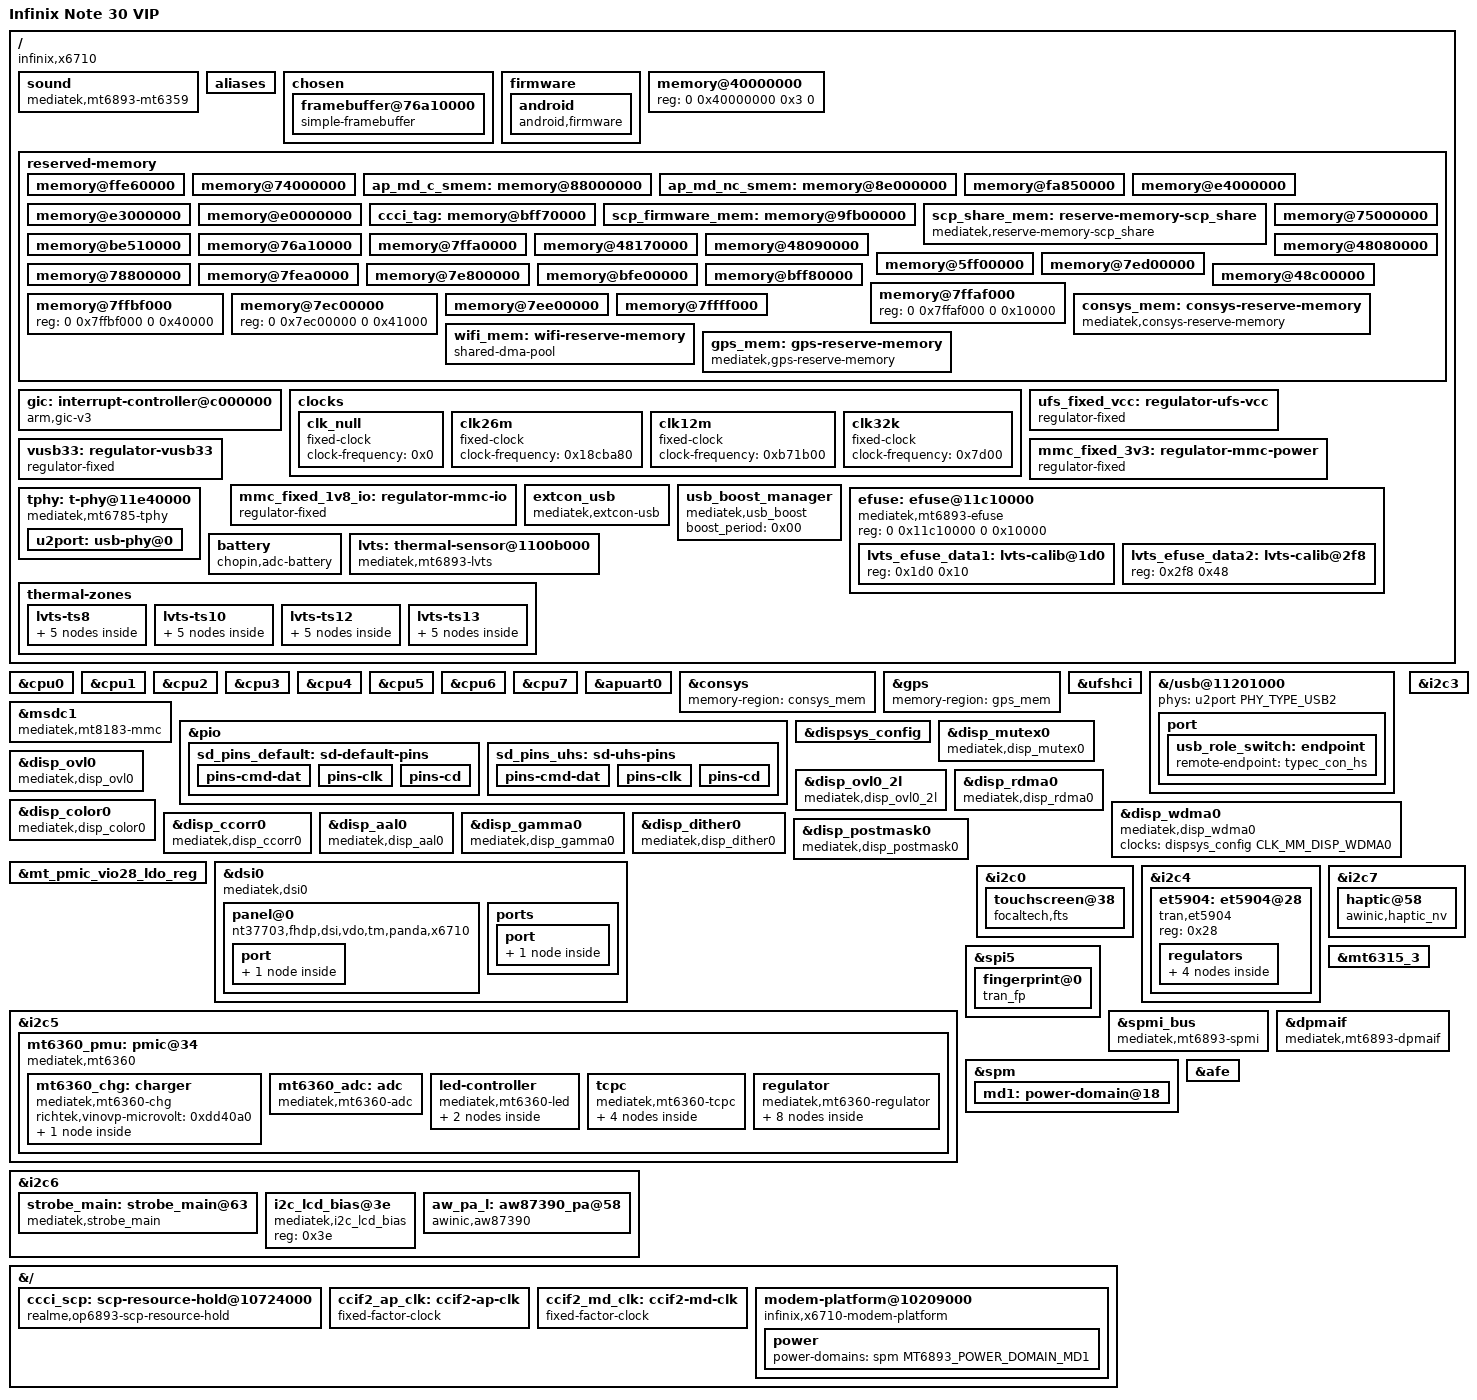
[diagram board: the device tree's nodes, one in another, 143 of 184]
// SPDX-License-Identifier: GPL-2.0-only
/*
 * Infinix Note 30 VIP (X6710)
 *
 * MediaTek MT6893Z/CZA handset.  The SoC side lives in mt6893.dtsi; this
 * file carries the board wiring: memory map, simplefb hand-off, PMIC,
 * UFS, USB, display, touch and the handful of I2C/SPI peripherals that
 * are populated on this board.
 */

/dts-v1/;

#include <dt-bindings/clock/mediatek,mt6893-clk.h>
#include <dt-bindings/power/mediatek,mt6893-power.h>
#include <dt-bindings/gpio/gpio.h>
#include <dt-bindings/interrupt-controller/arm-gic.h>
#include <dt-bindings/leds/common.h>
#include <dt-bindings/phy/phy.h>
#include <dt-bindings/thermal/mediatek,lvts-thermal.h>
#include <dt-bindings/thermal/thermal.h>
#include <dt-bindings/pinctrl/mt65xx.h>
#include <dt-bindings/reset/mediatek,mt6893-resets.h>
#include "mt6893.dtsi"

/ {
	model = "Infinix Note 30 VIP";
	chassis-type = "handset";
	compatible = "infinix,x6710", "mediatek,mt6893";

	interrupt-parent = <&gic>;
	#address-cells = <0x02>;
	#size-cells = <0x02>;

	/* Speaker card: AFE DL1 -> I2S3 -> stereo Awinic AW87390 smart PAs.
	 * The two AW87390 components (no DAI) attach as aux-devs.  The MTK AFE
	 * GPIO driver tolerates missing audio pinctrl states; I2S3 pins are
	 * muxed by the bootloader handoff, as with the display. */
	sound: sound {
		compatible = "mediatek,mt6893-mt6359";
		model = "mt6893_mt6359";
		mediatek,platform = <&afe>;
		status = "okay";

		/* Only one AW87390 is populated (i2c6 @0x58); the old second
		 * entry at 0x59 does not respond and blocked card binding.
		 */
		aux-devs = <&aw_pa_l>;
	};

	aliases {
		serial0 = &apuart0;

		/* The downstream DRM stack uses these IDs to identify blocks. */
		ovl0 = &disp_ovl0;
		ovl3 = &disp_ovl0_2l;
		rdma0 = &disp_rdma0;
		wdma0 = &disp_wdma0;
		color0 = &disp_color0;
		ccorr0 = &disp_ccorr0;
		aal0 = &disp_aal0;
		gamma0 = &disp_gamma0;
		dither0 = &disp_dither0;
		rsz0 = &disp_rsz0;
		postmask0 = &disp_postmask0;
		dsi0 = &dsi0;
	};

	chosen {
		#address-cells = <0x02>;
		#size-cells = <0x02>;
		ranges;

		stdout-path = "serial0:921600n8";

		/* 48-byte LK handoff header from the stock X6710 FDT:
		 * base=0xbff70000 size=0xa68 error=0 version=3 count=20
		 * load_flag=1, md_errors=0, tail padding=0. */
		ccci,modem_info_v2 = <0xf7bf 0x00 0x680a0000 0x00
				      0x3000000 0x14000000 0x1000000 0x00
				      0x00 0x00 0x00 0x00>;

		bootargs = "console=tty0 console=ttyS0,921600n8 clk_ignore_unused regulator_ignore_unused pd_ignore_unused loglevel=7 debug";

		framebuffer@76a10000 {
			compatible = "simple-framebuffer";
			reg = <0 0x76a10000 0 0x1df0000>;
			width = <1080>;
			height = <2400>;
			stride = <((1080 + 8) * 4)>;
			format = "a8r8g8b8";
			status = "okay";
		};
	};

	firmware {
		android {
			compatible = "android,firmware";
			hardware = "mt6893";
			mode = "normal";
		};
	};

	memory@40000000 {
		device_type = "memory";
		reg = <0 0x40000000 0x3 0>;
	};

	reserved-memory {
		#address-cells = <0x02>;
		#size-cells = <0x02>;
		ranges;

		/* ATF / secure monitor log */
		memory@ffe60000 {
			reg = <0 0xffe60000 0 0x190000>;
			no-map;
		};

		memory@74000000 {
			reg = <0 0x74000000 0 0xe30000>;
			no-map;
		};

		ap_md_c_smem: memory@88000000 {
			reg = <0 0x88000000 0 0x5560000>;
			no-map;
		};

		ap_md_nc_smem: memory@8e000000 {
			reg = <0 0x8e000000 0 0x910000>;
			no-map;
		};

		memory@fa850000 {
			reg = <0 0xfa850000 0 0x37b0000>;
			no-map;
		};

		memory@e4000000 {
			reg = <0 0xe4000000 0 0x7eb0000>;
			no-map;
		};

		memory@e3000000 {
			reg = <0 0xe3000000 0 0xf0000>;
			no-map;
		};

		memory@e0000000 {
			reg = <0 0xe0000000 0 0x2080000>;
			no-map;
		};

		ccci_tag: memory@bff70000 {
			reg = <0 0xbff70000 0 0x10000>;
			no-map;
		};

		/* Stock X6710 mblock-23-SCP-reserved: SCP firmware/TCM handoff. */
		scp_firmware_mem: memory@9fb00000 {
			reg = <0 0x9fb00000 0 0x400000>;
			no-map;
		};

		/* Stock X6710 reserve-memory-scp_share geometry. */
		scp_share_mem: reserve-memory-scp_share {
			compatible = "mediatek,reserve-memory-scp_share";
			no-map;
			size = <0 0x320000>;
			alignment = <0 0x1000000>;
			alloc-ranges = <0 0x50000000 0 0x40000000>;
		};

		memory@75000000 {
			reg = <0 0x75000000 0 0x10000>;
			no-map;
		};

		memory@be510000 {
			reg = <0 0xbe510000 0 0x18f0000>;
			no-map;
		};

		/* framebuffer handed over by uniLoader */
		memory@76a10000 {
			reg = <0 0x76a10000 0 0x1df0000>;
			no-map;
		};

		memory@7ffa0000 {
			reg = <0 0x7ffa0000 0 0x8000>;
			no-map;
		};

		memory@48170000 {
			reg = <0 0x48170000 0 0x10000>;
			no-map;
		};

		/* ramoops (see ramoops.mem_address=0x48090000) */
		memory@48090000 {
			reg = <0 0x48090000 0 0xe0000>;
			no-map;
		};

		memory@48080000 {
			reg = <0 0x48080000 0 0x10000>;
			no-map;
		};

		memory@5ff00000 {
			reg = <0 0x5ff00000 0 0x80000>;
			no-map;
		};

		memory@7ed00000 {
			reg = <0 0x7ed00000 0 0x100000>;
			no-map;
		};

		memory@78800000 {
			reg = <0 0x78800000 0 0x6000000>;
			no-map;
		};

		memory@7fea0000 {
			reg = <0 0x7fea0000 0 0x100000>;
			no-map;
		};

		memory@7e800000 {
			reg = <0 0x7e800000 0 0x400000>;
			no-map;
		};

		memory@bfe00000 {
			reg = <0 0xbfe00000 0 0x40000>;
			no-map;
		};

		memory@bff80000 {
			reg = <0 0xbff80000 0 0x80000>;
			no-map;
		};

		memory@48c00000 {
			reg = <0 0x48c00000 0 0x200000>;
			no-map;
		};

		memory@7ffaf000 {
			reg = <0 0x7ffaf000 0 0x10000>;
		};

		memory@7ffbf000 {
			reg = <0 0x7ffbf000 0 0x40000>;
		};

		memory@7ec00000 {
			reg = <0 0x7ec00000 0 0x41000>;
		};

		memory@7ee00000 {
			reg = <0 0x7ee00000 0 0x1000000>;
			no-map;
		};

		memory@7ffff000 {
			reg = <0 0x7ffff000 0 0x1000>;
			no-map;
		};

		/* Connectivity firmware/coredump EMI, allocated below 0x90000000. */
		consys_mem: consys-reserve-memory {
			compatible = "mediatek,consys-reserve-memory";
			no-map;
			size = <0x0 0x450000>;
			alignment = <0x0 0x1000000>;
			alloc-ranges = <0x0 0x50000000 0x0 0x40000000>;
		};

		wifi_mem: wifi-reserve-memory {
			compatible = "shared-dma-pool";
			no-map;
			size = <0x0 0xf20000>;
			alignment = <0x0 0x1000000>;
			alloc-ranges = <0x0 0x40000000 0x0 0x80000000>;
		};

		gps_mem: gps-reserve-memory {
			compatible = "mediatek,gps-reserve-memory";
			no-map;
			size = <0x0 0x100000>;
			alignment = <0x0 0x100000>;
			alloc-ranges = <0x0 0x40000000 0x0 0x80000000>;
		};
	};

	/* GIC lives in the board file for this SoC family. */
	gic: interrupt-controller@c000000 {
		compatible = "arm,gic-v3";
		#interrupt-cells = <0x03>;
		#address-cells = <0x02>;
		#size-cells = <0x02>;
		#redistributor-regions = <0x01>;
		interrupt-parent = <&gic>;
		interrupt-controller;
		reg = <0x0 0xc000000 0x0 0x40000 0x0 0xc040000 0x0 0x200000>;
		interrupts = <0x01 0x09 0x04>;
	};

	clocks {
		clk_null: clk_null {
			compatible = "fixed-clock";
			#clock-cells = <0x00>;
			clock-frequency = <0x0>;
		};

		clk26m: clk26m {
			compatible = "fixed-clock";
			#clock-cells = <0x00>;
			clock-frequency = <0x18cba80>;
		};

		clk12m: clk12m {
			compatible = "fixed-clock";
			#clock-cells = <0x00>;
			clock-frequency = <0xb71b00>;
		};

		clk32k: clk32k {
			compatible = "fixed-clock";
			#clock-cells = <0x00>;
			clock-frequency = <0x7d00>;
		};
	};

	/* UFS VCC (always-on 2.9V rail). */
	ufs_fixed_vcc: regulator-ufs-vcc {
		compatible = "regulator-fixed";
		regulator-name = "vreg_ufs_vcc";
		regulator-min-microvolt = <0x2dc6c0>;
		regulator-max-microvolt = <0x2dc6c0>;
		regulator-always-on;
		regulator-boot-on;
	};

	/* USB PHY 3.3V rail. */
	vusb33: regulator-vusb33 {
		compatible = "regulator-fixed";
		regulator-name = "vusb33";
		regulator-min-microvolt = <0x325aa0>;
		regulator-max-microvolt = <0x325aa0>;
		regulator-always-on;
	};

	/* eMMC / SD rails (the SoC msdc blocks refer to these). */
	mmc_fixed_3v3: regulator-mmc-power {
		compatible = "regulator-fixed";
		regulator-name = "mmc_power";
		regulator-min-microvolt = <0x325aa0>;
		regulator-max-microvolt = <0x325aa0>;
		enable-active-high;
		regulator-always-on;
	};

	mmc_fixed_1v8_io: regulator-mmc-io {
		compatible = "regulator-fixed";
		regulator-name = "mmc_io";
		regulator-min-microvolt = <0x1b7740>;
		regulator-max-microvolt = <0x1b7740>;
		enable-active-high;
		regulator-always-on;
	};

	extcon_usb: extcon_usb {
		compatible = "mediatek,extcon-usb";
	};

	usb_boost_manager {
		compatible = "mediatek,usb_boost";
		boost_period = <0x00>;
	};

	tphy: t-phy@11e40000 {
		compatible = "mediatek,mt6785-tphy", "mediatek,generic-tphy-v2";
		#address-cells = <0x01>;
		#size-cells = <0x01>;
		ranges = <0x0 0x0 0x11e40000 0x1000>;
		status = "okay";

		u2port: usb-phy@0 {
			reg = <0x0 0x1000>;
			clocks = <&clk26m>;
			clock-names = "ref";
			#phy-cells = <0x01>;
			mediatek,eye-vrt = <0x04>;
			mediatek,eye-term = <0x04>;
			mediatek,intr = <0x1e>;
			mediatek,discth = <0x07>;
			mediatek,force-session-valid;
			status = "okay";
		};
	};

	/* LVTS calibration eFuse (stock data1 @0x1d0/0x10, data2 @0x2f8/0x48). */
	efuse: efuse@11c10000 {
		compatible = "mediatek,mt6893-efuse", "mediatek,efuse";
		reg = <0 0x11c10000 0 0x10000>;
		#address-cells = <1>;
		#size-cells = <1>;

		lvts_efuse_data1: lvts-calib@1d0 {
			reg = <0x1d0 0x10>;
		};
		lvts_efuse_data2: lvts-calib@2f8 {
			reg = <0x2f8 0x48>;
		};
	};

	/* Fuel gauge stand-in: OCV from the MT6360 VBAT ADC, mapped through the
	 * stock battery0_profile_t1 curve.  No vendor gauge driver upstream. */
	battery {
		compatible = "chopin,adc-battery";
		io-channels = <&mt6360_adc 4>;
		io-channel-names = "vbat";
		power-supplies = <&mt6360_chg>;
	};

	lvts: thermal-sensor@1100b000 {
		compatible = "mediatek,mt6893-lvts";
		reg = <0 0x1100b000 0 0x1000>;
		interrupts = <GIC_SPI 169 IRQ_TYPE_LEVEL_HIGH>;
		clocks = <&infracfg_ao CLK_INFRA_AO_THERM>;
		clock-names = "lvts_clk";
		nvmem-cells = <&lvts_efuse_data1>, <&lvts_efuse_data2>;
		nvmem-cell-names = "lvts-calib-data-1", "lvts-calib-data-2";
		#thermal-sensor-cells = <1>;
		status = "okay";
	};

	thermal-zones {
		lvts-ts8 {
			polling-delay = <1000>;
			polling-delay-passive = <250>;
			thermal-sensors = <&lvts MT6893_LVTS_TS8>;

			trips {
				ts8_alert: trip-alert {
					temperature = <70000>;
					hysteresis = <2000>;
					type = "passive";
				};
				trip-crit {
					temperature = <95000>;
					hysteresis = <2000>;
					type = "critical";
				};
			};

			cooling-maps {
				map {
					trip = <&ts8_alert>;
					cooling-device = <&cpu0 THERMAL_NO_LIMIT THERMAL_NO_LIMIT>,
							 <&cpu1 THERMAL_NO_LIMIT THERMAL_NO_LIMIT>,
							 <&cpu2 THERMAL_NO_LIMIT THERMAL_NO_LIMIT>,
							 <&cpu3 THERMAL_NO_LIMIT THERMAL_NO_LIMIT>,
							 <&cpu4 THERMAL_NO_LIMIT THERMAL_NO_LIMIT>,
							 <&cpu5 THERMAL_NO_LIMIT THERMAL_NO_LIMIT>,
							 <&cpu6 THERMAL_NO_LIMIT THERMAL_NO_LIMIT>,
							 <&cpu7 THERMAL_NO_LIMIT THERMAL_NO_LIMIT>;
				};
			};
		};

		lvts-ts10 {
			polling-delay = <1000>;
			polling-delay-passive = <250>;
			thermal-sensors = <&lvts MT6893_LVTS_TS10>;

			trips {
				ts10_alert: trip-alert {
					temperature = <70000>;
					hysteresis = <2000>;
					type = "passive";
				};
				trip-crit {
					temperature = <95000>;
					hysteresis = <2000>;
					type = "critical";
				};
			};

			cooling-maps {
				map {
					trip = <&ts10_alert>;
					cooling-device = <&cpu0 THERMAL_NO_LIMIT THERMAL_NO_LIMIT>,
							 <&cpu1 THERMAL_NO_LIMIT THERMAL_NO_LIMIT>,
							 <&cpu2 THERMAL_NO_LIMIT THERMAL_NO_LIMIT>,
							 <&cpu3 THERMAL_NO_LIMIT THERMAL_NO_LIMIT>,
							 <&cpu4 THERMAL_NO_LIMIT THERMAL_NO_LIMIT>,
							 <&cpu5 THERMAL_NO_LIMIT THERMAL_NO_LIMIT>,
							 <&cpu6 THERMAL_NO_LIMIT THERMAL_NO_LIMIT>,
							 <&cpu7 THERMAL_NO_LIMIT THERMAL_NO_LIMIT>;
				};
			};
		};

		lvts-ts12 {
			polling-delay = <1000>;
			polling-delay-passive = <250>;
			thermal-sensors = <&lvts MT6893_LVTS_TS12>;

			trips {
				ts12_alert: trip-alert {
					temperature = <70000>;
					hysteresis = <2000>;
					type = "passive";
				};
				trip-crit {
					temperature = <95000>;
					hysteresis = <2000>;
					type = "critical";
				};
			};

			cooling-maps {
				map {
					trip = <&ts12_alert>;
					cooling-device = <&cpu0 THERMAL_NO_LIMIT THERMAL_NO_LIMIT>,
							 <&cpu1 THERMAL_NO_LIMIT THERMAL_NO_LIMIT>,
							 <&cpu2 THERMAL_NO_LIMIT THERMAL_NO_LIMIT>,
							 <&cpu3 THERMAL_NO_LIMIT THERMAL_NO_LIMIT>,
							 <&cpu4 THERMAL_NO_LIMIT THERMAL_NO_LIMIT>,
							 <&cpu5 THERMAL_NO_LIMIT THERMAL_NO_LIMIT>,
							 <&cpu6 THERMAL_NO_LIMIT THERMAL_NO_LIMIT>,
							 <&cpu7 THERMAL_NO_LIMIT THERMAL_NO_LIMIT>;
				};
			};
		};

		lvts-ts13 {
			polling-delay = <1000>;
			polling-delay-passive = <250>;
			thermal-sensors = <&lvts MT6893_LVTS_TS13>;

			trips {
				ts13_alert: trip-alert {
					temperature = <70000>;
					hysteresis = <2000>;
					type = "passive";
				};
				trip-crit {
					temperature = <95000>;
					hysteresis = <2000>;
					type = "critical";
				};
			};

			cooling-maps {
				map {
					trip = <&ts13_alert>;
					cooling-device = <&cpu0 THERMAL_NO_LIMIT THERMAL_NO_LIMIT>,
							 <&cpu1 THERMAL_NO_LIMIT THERMAL_NO_LIMIT>,
							 <&cpu2 THERMAL_NO_LIMIT THERMAL_NO_LIMIT>,
							 <&cpu3 THERMAL_NO_LIMIT THERMAL_NO_LIMIT>,
							 <&cpu4 THERMAL_NO_LIMIT THERMAL_NO_LIMIT>,
							 <&cpu5 THERMAL_NO_LIMIT THERMAL_NO_LIMIT>,
							 <&cpu6 THERMAL_NO_LIMIT THERMAL_NO_LIMIT>,
							 <&cpu7 THERMAL_NO_LIMIT THERMAL_NO_LIMIT>;
				};
			};
		};
	};
};

/* LVTS trips drive cpufreq cooling; every CPU must be a cooling device. */
&cpu0 {
	#cooling-cells = <2>;
};
&cpu1 {
	#cooling-cells = <2>;
};
&cpu2 {
	#cooling-cells = <2>;
};
&cpu3 {
	#cooling-cells = <2>;
};
&cpu4 {
	#cooling-cells = <2>;
};
&cpu5 {
	#cooling-cells = <2>;
};
&cpu6 {
	#cooling-cells = <2>;
};
&cpu7 {
	#cooling-cells = <2>;
};

/* ------------------------------------------------------------------ */
/* UART                                                                */
/* ------------------------------------------------------------------ */

&apuart0 {
	status = "okay";
};

/* Downstream conninfra requires its private EMI carveout. */
&consys {
	#thermal-sensor-cells = <0x00>;
	memory-region = <&consys_mem>;
};

&gps {
	memory-region = <&gps_mem>;
};

/*
 * X6710's vendor tree exposes only the HCI, UniPro and crypto resets.
 * Do not reset the MPHY: this device's ATF does not implement the
 * UFS_MPHY_BACKUP/RESTORE SMC needed to preserve its state across reset.
 */
&ufshci {
	resets = <&infracfg_ao MT6893_INFRA_RST1_UFSHCI_SW_RST>,
		 <&infracfg_ao MT6893_INFRA_RST2_UNIPRO_SW_RST>,
		 <&infracfg_ao MT6893_INFRA_RST3_UFSCPT_SW_RST>;
	reset-names = "hci_rst", "unipro_rst", "crypto_rst";
};

/* The generic T-PHY binding requires a PHY type argument. */
&{/usb@11201000} {
	phys = <&u2port PHY_TYPE_USB2>;

	/*
	 * The OTG boost is owned by the MT6360 charger and driven through the
	 * TCPM power-role state machine, not by the USB controller.
	 */
	/delete-property/ vbus-supply;

	/* Role-switch endpoint consumed by the MT6360 Type-C port manager. */
	port {
		usb_role_switch: endpoint {
			remote-endpoint = <&typec_con_hs>;
		};
	};
};

/* ------------------------------------------------------------------ */
/* SD card (MSDC1)                                                     */
/* ------------------------------------------------------------------ */

/*
 * The SoC dtsi describes msdc1 with the downstream binding.  Reuse the
 * node but bind it to the mainline mtk-sd driver, using the MT6360 LDO5
 * (VMCH) as card power and LDO3 (VMC) as switchable I/O supply.
 */
&msdc1 {
	compatible = "mediatek,mt8183-mmc";
	reg = <0x00 0x11240000 0x00 0x1000>, <0x00 0x11e10000 0x00 0x1000>;
	clocks = <&topckgen CLK_TOP_MSDC30_1_SEL>,
		 <&infracfg_ao CLK_INFRA_AO_MSDC1>,
		 <&infracfg_ao CLK_INFRA_AO_MSDC1_SRC>;
	clock-names = "source", "hclk", "source_cg";
	assigned-clocks = <&topckgen CLK_TOP_MSDC30_1_SEL>;
	assigned-clock-parents = <&topckgen CLK_TOP_MSDCPLL_D2>;
	pinctrl-names = "default", "state_uhs";
	pinctrl-0 = <&sd_pins_default>;
	pinctrl-1 = <&sd_pins_uhs>;
	bus-width = <0x04>;
	max-frequency = <0xbebc200>;
	cap-sd-highspeed;
	sd-uhs-sdr12;
	sd-uhs-sdr25;
	sd-uhs-sdr50;
	sd-uhs-sdr104;
	sd-uhs-ddr50;
	no-mmc;
	no-sdio;
	cd-gpios = <&pio 0x17 GPIO_ACTIVE_HIGH>;
	vmmc-supply = <&mt_pmic_vmch_ldo_reg>;
	vqmmc-supply = <&mt_pmic_vmc_ldo_reg>;
	status = "okay";
};

&pio {
	/*
	 * MSDC1: CLK on GPIO51, CMD on GPIO52, DAT0..3 on GPIO54/56/55/53.
	 * CD stays a plain GPIO input (GPIO23) with a pull-up.
	 */
	sd_pins_default: sd-default-pins {
		pins-cmd-dat {
			pinmux = <0x3401 0x3601 0x3801 0x3701 0x3501>;
			input-enable;
			bias-pull-up = <MTK_PUPD_SET_R1R0_01>;
			drive-strength = <0x08>;
		};

		pins-clk {
			pinmux = <0x3301>;
			input-enable;
			bias-pull-down = <MTK_PUPD_SET_R1R0_10>;
			drive-strength = <0x08>;
		};

		pins-cd {
			pinmux = <0x1700>;
			input-enable;
			bias-pull-up;
		};
	};

	sd_pins_uhs: sd-uhs-pins {
		pins-cmd-dat {
			pinmux = <0x3401 0x3601 0x3801 0x3701 0x3501>;
			input-enable;
			bias-pull-up = <MTK_PUPD_SET_R1R0_01>;
			drive-strength = <0x08>;
		};

		pins-clk {
			pinmux = <0x3301>;
			input-enable;
			bias-pull-down = <MTK_PUPD_SET_R1R0_10>;
			drive-strength = <0x08>;
		};

		pins-cd {
			pinmux = <0x1700>;
			input-enable;
			bias-pull-up;
		};
	};
};

/* ------------------------------------------------------------------ */
/* Display                                                             */
/* ------------------------------------------------------------------ */

/* Match the two top clocks and component identities in the vendor DT. */
&dispsys_config {
	clocks = <&dispsys_config CLK_MM_CK_26_MHZ>,
		 <&dispsys_config CLK_MM_DISP_MUTEX>;
	clock-num = <0x02>;
	/*
	 * mmsys is the clock supplier for iommu0, which in turn is this
	 * node's IOMMU.  The mutual probe dependency can never resolve and
	 * both devices wait for the deferred-probe timeout.  mmsys does no
	 * DMA of its own, so drop the link.
	 */
	/delete-property/ iommus;
};

&disp_mutex0 {
	compatible = "mediatek,disp_mutex0", "mediatek,mt6885-disp-mutex";
};

/*
 * iommu0 (m4u@1411a000) uses the downstream "mediatek,iommu_v0" binding,
 * for which this kernel has no driver.  Listing it in "iommus" makes each
 * display component return -EPROBE_DEFER until the deferred-probe timeout
 * expires, which delays panel probe by a couple of seconds.  The IOMMU was
 * never actually attached, so drop the references.
 */
&disp_ovl0 {
	compatible = "mediatek,disp_ovl0", "mediatek,mt6885-disp-ovl";
	/delete-property/ iommus;
};

&disp_ovl0_2l {
	compatible = "mediatek,disp_ovl0_2l", "mediatek,mt6885-disp-ovl";
	/delete-property/ iommus;
};

&disp_rdma0 {
	compatible = "mediatek,disp_rdma0", "mediatek,mt6885-disp-rdma";
	/delete-property/ iommus;
};

&disp_wdma0 {
	compatible = "mediatek,disp_wdma0", "mediatek,mt6885-disp-wdma";
	/delete-property/ iommus;
	clocks = <&dispsys_config CLK_MM_DISP_WDMA0>;
};

&disp_color0 {
	compatible = "mediatek,disp_color0", "mediatek,mt6885-disp-color";
};

&disp_ccorr0 {
	compatible = "mediatek,disp_ccorr0", "mediatek,mt6885-disp-ccorr";
	ccorr_bit = <0x0c>;
	ccorr_num_per_pipe = <0x01>;
	ccorr_linear_per_pipe = <0x01>;
	ccorr_prim_force_linear = <0x00>;
	ccorr_linear = <0x00>;
};

&disp_aal0 {
	compatible = "mediatek,disp_aal0", "mediatek,mt6885-disp-aal";
	mtk_aal_support = <0x01>;
	mtk_dre30_support = <0x00>;
};

&disp_gamma0 {
	compatible = "mediatek,disp_gamma0", "mediatek,mt6885-disp-gamma";
	gamma_data_mode = <0x00>;
	color_protect_red = <0x00>;
	color_protect_green = <0x00>;
	color_protect_blue = <0x00>;
	color_protect_white = <0x00>;
	color_protect_black = <0x00>;
	color_protect_lsb = <0x00>;
};

&disp_dither0 {
	compatible = "mediatek,disp_dither0", "mediatek,mt6885-disp-dither";
	pure_clr_det = <0x00>;
	pure_clr_num = <0x07>;
	pure_clr_rgb = <0xff 0x00 0x00 0x00 0xff 0x00 0x00 0x00 0xff
			0xff 0xff 0x00 0xff 0x00 0xff 0x00 0xff 0xff 0xff
			0xff 0xff>;
};

&disp_postmask0 {
	compatible = "mediatek,disp_postmask0", "mediatek,mt6885-disp-postmask";
	/delete-property/ iommus;
};

&mt_pmic_vio28_ldo_reg {
	regulator-min-microvolt = <2800000>;
	regulator-max-microvolt = <2800000>;
	regulator-always-on;
	regulator-boot-on;
};

&dsi0 {
	compatible = "mediatek,dsi0", "mediatek,mt6885-dsi";
	status = "okay";
	#address-cells = <0x01>;
	#size-cells = <0x00>;

	panel@0 {
		compatible = "nt37703,fhdp,dsi,vdo,tm,panda,x6710";
		reg = <0x00>;
		panel-boot-on;
		reset-gpios = <&pio 0x2a 0x00>;
		vci-supply = <&mt_pmic_vio28_ldo_reg>;
		dvdd-supply = <&et5904_ldo14>;
		dvdd2-supply = <&et5904_ldo24>;
		status = "okay";

		port {
			panel_in: endpoint {
				remote-endpoint = <&dsi_out>;
			};
		};
	};

	ports {
		port {
			dsi_out: endpoint {
				remote-endpoint = <&panel_in>;
			};
		};
	};
};

/* ------------------------------------------------------------------ */
/* I2C buses                                                           */
/* ------------------------------------------------------------------ */

/* i2c0: FocalTech FT3681 touch panel */
&i2c0 {
	status = "okay";
	/* Match the vendor touch bus: open-drain, 400 kHz. */
	mediatek,use-open-drain;
	clock-frequency = <400000>;

	touchscreen@38 {
		compatible = "focaltech,fts";
		reg = <0x38>;
		/* vtouch is MT6360 LDO2 ("vtp") in the stock design. */
		vtouch-supply = <&mt_pmic_vtp_ldo_reg>;
		interrupt-parent = <&pio>;
		interrupts = <0x15 0x02>;
		/* FT3681 reset is active low (vendor drives 0 then 1). */
		reset-gpios = <&pio 0x14 GPIO_ACTIVE_LOW>;
		focaltech,max-touch-number = <0x0a>;
		focaltech,display-coords = <0x00 0x00 0x438 0x960>;
		status = "okay";
	};
};

/* i2c3: NFC and charger companions */
&i2c3 {
	status = "okay";
};

/* i2c4: ET5904 camera/display bias regulators */
&i2c4 {
	status = "okay";

	et5904: et5904@28 {
		compatible = "tran,et5904";
		reg = <0x28>;

		regulators {
			et5904_ldo14: ET5904LDO14 {
				regulator-name = "ET5904LDO14";
				regulator-min-microvolt = <0x1b7740>;
				regulator-max-microvolt = <0x1b7740>;
				regulator-boot-on;
			};

			et5904_ldo24: ET5904LDO24 {
				regulator-name = "ET5904LDO24";
				regulator-min-microvolt = <0x149970>;
				regulator-max-microvolt = <0x149970>;
				regulator-boot-on;
			};

			et5904_ldo34: ET5904LDO34 {
				regulator-name = "ET5904LDO34";
				regulator-min-microvolt = <0x124f80>;
				regulator-max-microvolt = <0x325aa0>;
			};

			et5904_ldo44: ET5904LDO44 {
				regulator-name = "ET5904LDO44";
				regulator-min-microvolt = <0x124f80>;
				regulator-max-microvolt = <0x325aa0>;
			};
		};
	};
};

/* i2c5: MT6360 PMIC / charger / Type-C */
&i2c5 {
	status = "okay";

	/* The PMIC bus is a GIC SPI; do not rely on inheritance here. */
	interrupt-parent = <&gic>;

	/*
	 * The MT6360 is only rated for 1 MHz I2C and the 3.4 MHz bus speed
	 * inherited from the vendor DTS makes charger/TCPC register accesses
	 * time out, which in turn makes the OPA (OTG VBUS) writes fail.
	 */
	clock-frequency = <400000>;

	mt6360_pmu: pmic@34 {
		compatible = "mediatek,mt6360";
		reg = <0x34>;
		interrupt-parent = <&pio>;
		interrupts = <0x18 0x02>;
		interrupt-names = "IRQB";
		interrupt-controller;
		#interrupt-cells = <0x01>;
		wakeup-source;
		status = "okay";

		mt6360_chg: charger {
			compatible = "mediatek,mt6360-chg";
			richtek,vinovp-microvolt = <0xdd40a0>;
			status = "okay";

			otg_vbus: usb-otg-vbus-regulator {
				regulator-name = "usb-otg-vbus";
				regulator-min-microvolt = <0x438528>;
				regulator-max-microvolt = <0x58e1e8>;
			};
		};

		mt6360_adc: adc {
			compatible = "mediatek,mt6360-adc";
			#io-channel-cells = <0x01>;
		};

		/* Camera flash: the two MT6360 FLED channels (reg 4/5 = FLASH1/2).
		 * Values match the stock device.dts (400 mA torch, 1.5 A flash,
		 * 1.248 s timeout); properties use the mainline binding names. */
		led-controller {
			compatible = "mediatek,mt6360-led";
			#address-cells = <1>;
			#size-cells = <0>;

			led@4 {
				reg = <4>;
				function = LED_FUNCTION_FLASH;
				color = <LED_COLOR_ID_WHITE>;
				function-enumerator = <1>;
				led-max-microamp = <400000>;
				flash-max-microamp = <1500000>;
				flash-max-timeout-us = <1248000>;
			};

			led@5 {
				reg = <5>;
				function = LED_FUNCTION_FLASH;
				color = <LED_COLOR_ID_WHITE>;
				function-enumerator = <2>;
				led-max-microamp = <400000>;
				flash-max-microamp = <1500000>;
				flash-max-timeout-us = <1248000>;
			};
		};

		tcpc {
			compatible = "mediatek,mt6360-tcpc";
			interrupt-parent = <&pio>;
			interrupts = <0x19 0x08>;
			interrupt-names = "PD_IRQB";
			status = "okay";
			vbus-supply = <&otg_vbus>;

			connector {
				compatible = "usb-c-connector";
				label = "USB-C";
				data-role = "dual";
				power-role = "dual";
				try-power-role = "sink";
				op-sink-microwatt = <0x19bfcc0>;
				source-pdos = <0x4019064>;
				sink-pdos = <0x401912c 0x402d12c 0x403c0e1>;

				ports {
					#address-cells = <0x01>;
					#size-cells = <0x00>;

					port@0 {
						reg = <0x00>;
						typec_con_hs: endpoint {
							remote-endpoint = <&usb_role_switch>;
						};
					};
				};
			};
		};

		/* The driver looks this node up by name "regulator". */
		regulator {
			compatible = "mediatek,mt6360-regulator";

			buck1 {
				regulator-name = "VMDLA";
				regulator-min-microvolt = <0x493e0>;
				regulator-max-microvolt = <0x13d620>;
				regulator-always-on;
			};

			buck2 {
				regulator-name = "VDRAM1";
				regulator-min-microvolt = <0x493e0>;
				regulator-max-microvolt = <0x13d620>;
				regulator-always-on;
			};

			mt_pmic_vfp_ldo_reg: ldo1 {
				regulator-name = "VFP";
				regulator-min-microvolt = <0x124f80>;
				regulator-max-microvolt = <0x36ee80>;
			};

			mt_pmic_vtp_ldo_reg: ldo2 {
				regulator-name = "vtp";
				regulator-min-microvolt = <0x124f80>;
				regulator-max-microvolt = <0x36ee80>;
			};

			mt_pmic_vmc_ldo_reg: ldo3 {
				regulator-name = "VMC";
				regulator-min-microvolt = <0x124f80>;
				regulator-max-microvolt = <0x36ee80>;
			};

			mt_pmic_vmch_ldo_reg: ldo5 {
				regulator-name = "VMCH";
				regulator-min-microvolt = <0x2932e0>;
				regulator-max-microvolt = <0x36ee80>;
			};

			ldo6 {
				regulator-name = "VMDDR";
				regulator-min-microvolt = <0x7a120>;
				regulator-max-microvolt = <0x200b20>;
			};

			ldo7 {
				regulator-name = "VDRAM2";
				regulator-min-microvolt = <0x7a120>;
				regulator-max-microvolt = <0x200b20>;
			};
		};
	};
};

/* i2c6: display bias, speaker amplifier and misc companions */
&i2c6 {
	status = "okay";

	/* Awinic AW36515 flashlight (stock "strobe_main" @ 0x63). */
	strobe_main: strobe_main@63 {
		compatible = "mediatek,strobe_main";
		reg = <0x63>;
		hwen-gpios = <&pio 12 GPIO_ACTIVE_HIGH>;
		status = "okay";
	};

	i2c_lcd_bias@3e {
		compatible = "mediatek,i2c_lcd_bias";
		reg = <0x3e>;
		status = "okay";
	};

	/* Stereo Awinic AW87390 smart PAs (chip ID 0x76).  Mainline driver
	 * sound/soc/codecs/aw87390.c; firmware /lib/firmware/aw87390_acf.bin.
	 * The stock "dev_index" is replaced by awinic,audio-channel. */
	aw_pa_l: aw87390_pa@58 {
		compatible = "awinic,aw87390";
		reg = <0x58>;
		#sound-dai-cells = <0>;
		awinic,audio-channel = <0>;
		status = "okay";
	};

};

/* i2c7: AW8622X haptics */
&i2c7 {
	status = "okay";

	haptic@58 {
		compatible = "awinic,haptic_nv";
		reg = <0x58>;
		reset-gpios = <&pio 0x62 0x00>;
		irq-gpios = <&pio 0x00 0x00>;
		aw862xx_i2c_addr = <0x58>;
		aw8622x_vib_mode = <0x00>;
		aw8622x_vib_f0_pre = <0x92e>;
		status = "okay";
	};
};

/* ------------------------------------------------------------------ */
/* SPI                                                                 */
/* ------------------------------------------------------------------ */

/* spi5: fingerprint sensor */
&spi5 {
	status = "okay";
	#address-cells = <0x01>;
	#size-cells = <0x00>;

	fingerprint@0 {
		compatible = "tran_fp";
		reg = <0x00>;
		spi-max-frequency = <0x989680>;
		status = "okay";
	};
};

/* ------------------------------------------------------------------ */
/* MD1 modem (CCCI/CCIF) - Phase 1: hardware description               */
/* ------------------------------------------------------------------ */

/*
 * The vendor PMIF compatible is not bound by mainline's SPMI controller
 * driver; use the MT6893 string it does understand.
 */
&spmi_bus {
	compatible = "mediatek,mt6893-spmi";
	status = "okay";
};

/* MT6315 #3 supplies the modem's vmodem/vsram/vnr rails.  The mainline
 * regulator binding (compatible + "regulators" container + vbuck names) is
 * now set up in mt6893.dtsi. */
&mt6315_3 {
	status = "okay";
};

/* Complete the modem node from the vendor FDT: platform info, power flow,
 * SPM sleep control and the MT6315 / mt6359p supplies.  Reserved memory for
 * the modem is already described in /reserved-memory above. */
/* ------------------------------------------------------------------ */
/* MD1 modem — mainline CCCI driver (ported from op6893)               */
/* ------------------------------------------------------------------ */

/* CCCI DPMAIF binds only to "mediatek,mt6893-dpmaif" and expects five
 * named regions + two clocks; the SoC dtsi node uses the older binding. */
&dpmaif {
	compatible = "mediatek,mt6893-dpmaif";
	reg = <0 0x10014000 0 0x1000>,
	      <0 0x1022d000 0 0x1000>,
	      <0 0x1022c000 0 0x1000>,
	      <0 0x1022e000 0 0x1000>,
	      <0 0x10002000 0 0x1000>;
	reg-names = "ao-ul", "pd-ul", "pd-md-misc", "sram", "infra-ao-mem";
	clocks = <&infracfg_ao CLK_INFRA_AO_DPMAIF_MAIN>,
		 <&infracfg_ao CLK_INFRA_AO_DPMAIF>;
	clock-names = "dpmaif-main", "dpmaif";
	mediatek,infracfg = <&infracfg_ao>;
	status = "okay";
};

/* MD1 MTCMOS genpd: the SoC dtsi describes only the audio domain, so the
 * modem platform's lookup device has no supplier. Register MD1 (id 24) with
 * its real infracfg so dev_pm_domain_attach_by_id() can succeed. */
&spm {
	md1: power-domain@18 {
		reg = <MT6893_POWER_DOMAIN_MD1>;
		#power-domain-cells = <0>;
		mediatek,infracfg = <&infracfg_ao>;
		status = "okay";
	};
};

/* SCP resource-hold provider: required by the CCISM bridge for the
 * generation-bound SCP lease. Register/mbox layout matches the MT6893
 * vendor SCP node; only the three CCIF mbox interrupts are wired. */
&{/} {
	ccci_scp: scp-resource-hold@10724000 {
		compatible = "realme,op6893-scp-resource-hold";
		reg = <0 0x10724000 0 0x1000>,
		      <0 0x107fb000 0 0x1000>,
		      <0 0x107fc000 0 0x1000>,
		      <0 0x107fd000 0 0x1000>,
		      <0 0x107fe000 0 0x1000>,
		      <0 0x107ff000 0 0x1000>,
		      <0 0x10730000 0 0x1000>,
		      <0 0x10740000 0 0x1000>,
		      <0 0x10500000 0 0x180000>;
		reg-names = "scp-cfg", "mbox0", "mbox1", "mbox2", "mbox3", "mbox4",
			    "core0", "core1", "tcm";
		interrupts = <GIC_SPI 436 IRQ_TYPE_LEVEL_HIGH>,
			     <GIC_SPI 437 IRQ_TYPE_LEVEL_HIGH>,
			     <GIC_SPI 438 IRQ_TYPE_LEVEL_HIGH>,
			     <GIC_SPI 439 IRQ_TYPE_LEVEL_HIGH>,
			     <GIC_SPI 440 IRQ_TYPE_LEVEL_HIGH>;
		interrupt-names = "mbox0", "mbox1", "mbox2", "mbox3", "mbox4";
		clocks = <&topckgen CLK_TOP_SCP_SEL>;
		clock-names = "scp";
		mediatek,send-table = <0 0 9
			3 1 2
			4 1 1
			5 1 2
			6 1 1
			26 1 9
			33 1 10
			11 2 34
			14 3 1
			15 3 2
			16 3 1
			17 3 6
			18 3 2
			24 4 34>;
		mediatek,recv-table = <1 0 2 0
			2 0 26 0
			7 1 2 0
			8 1 10 0
			9 1 1 0
			10 1 2 0
			27 1 2 0
			28 1 5 0
			5 1 1 1
			34 1 10 0
			12 2 30 0
			20 3 10 0
			21 3 6 0
			22 3 1 0
			23 3 2 0
			15 3 1 1
			25 4 30 0>;
		mediatek,topckgen = <&topckgen>;
		mediatek,infracfg = <&infracfg_ao>;
		memory-region = <&scp_firmware_mem>, <&scp_share_mem>;
		memory-region-names = "firmware", "share";
		status = "okay";
	};

	/* CCIF2 clocks: logical aliases only. LK leaves the bank4 hardware gate
	 * set, so these mirror the proven op6893 dummy factors, which never read
	 * or write that gate. They give the CCISM bridge lifecycle references. */
	ccif2_ap_clk: ccif2-ap-clk {
		compatible = "fixed-factor-clock";
		#clock-cells = <0>;
		clocks = <&infracfg_ao CLK_INFRA_AO_CCIF_AP>;
		clock-mult = <1>;
		clock-div = <1>;
		clock-output-names = "ccif2-ap";
	};

	ccif2_md_clk: ccif2-md-clk {
		compatible = "fixed-factor-clock";
		#clock-cells = <0>;
		clocks = <&infracfg_ao CLK_INFRA_AO_CCIF_MD>;
		clock-mult = <1>;
		clock-div = <1>;
		clock-output-names = "ccif2-md";
	};

	modem-platform@10209000 {
		compatible = "infinix,x6710-modem-platform";
		mediatek,dpmaif = <&dpmaif>;
		reg = <0 0x10209000 0 0x1000>, <0 0x1020a000 0 0x1000>,
		      <0 0x1023c000 0 0x1000>, <0 0x1023d000 0 0x1000>;
		reg-names = "ccif-ap", "ccif-md", "ccif2-ap", "ccif2-md";
		interrupts = <GIC_SPI 194 IRQ_TYPE_LEVEL_HIGH>,
			     <GIC_SPI 195 IRQ_TYPE_LEVEL_HIGH>;
		interrupt-names = "data", "exception";
		memory-region = <&ccci_tag>, <&ap_md_nc_smem>, <&ap_md_c_smem>;
		memory-region-names = "tags", "noncached", "cached";
		md-vmodem-supply = <&mt6315_3_vbuck1>;
		md-vnr-supply = <&mt6315_3_vbuck3>;
		md-vsram-supply = <&mt6315_3_vbuck4>;
		md-vdigrf-supply = <&mt_pmic_vpu_buck_reg>;
		clocks = <&infracfg_ao CLK_INFRA_AO_CCIF_AP>,
			 <&infracfg_ao CLK_INFRA_AO_CCIF_MD>,
			 <&infracfg_ao CLK_INFRA_AO_CCIF1_AP>,
			 <&infracfg_ao CLK_INFRA_AO_CCIF1_MD>,
			 <&ccif2_ap_clk>, <&ccif2_md_clk>;
		clock-names = "ccif-ap", "ccif-md", "ccif1-ap", "ccif1-md",
			      "ccif2-ap", "ccif2-md";
		mediatek,scp = <&ccci_scp>;
		mediatek,spm = <&spm_syscon>;
		mediatek,infracfg = <&infracfg_ao>;
		mediatek,no-external-32k;
		/* Board scalars from this device's stock Android dmesg:
		 * "sbp=0x0,wmid[0x79]" and "c2k_flags 0x0; MD_GENERATION: 6297". */
		mediatek,wmid = <0x79>;
		mediatek,c2k-flags = <0x0>;
		status = "okay";

		power {
			power-domains = <&spm MT6893_POWER_DOMAIN_MD1>;
		};
	};
};

/* ------------------------------------------------------------------ */
/* Audio                                                               */
/* ------------------------------------------------------------------ */

/* Speaker card: AFE DL1 -> I2S3 -> stereo Awinic AW87390 smart PAs.
 * The two AW87390 components (no DAI) attach as aux-devs.  The MTK AFE GPIO
 * driver tolerates missing audio pinctrl states; I2S3 pins are muxed by the
 * bootloader handoff, as with the display. */
&afe {
	status = "okay";
};
